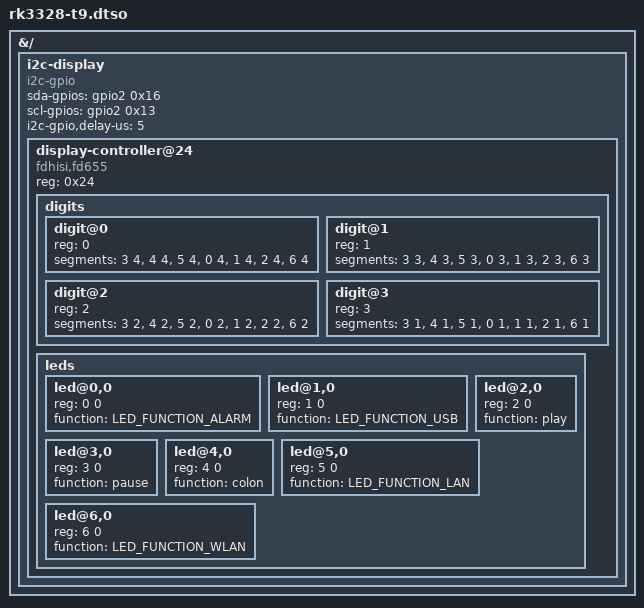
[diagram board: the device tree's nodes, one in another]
/dts-v1/;
/plugin/;

#include <dt-bindings/gpio/gpio.h>
#include <dt-bindings/leds/common.h>

&{/} {

	i2c-display {
		compatible = "i2c-gpio";
		sda-gpios = <&gpio2 0x16 (GPIO_ACTIVE_HIGH | GPIO_OPEN_DRAIN)>;
		scl-gpios = <&gpio2 0x13 (GPIO_ACTIVE_HIGH | GPIO_OPEN_DRAIN)>;
		i2c-gpio,delay-us = <5>;
		#address-cells = <1>;
		#size-cells = <0>;

		display-controller@24 {
			compatible = "fdhisi,fd655";
			reg = <0x24>;

			digits {
				#address-cells = <1>;
				#size-cells = <0>;
				digit@0 {
					reg = <0>;
					segments = <3 4>,
						   <4 4>,
						   <5 4>,
						   <0 4>,
						   <1 4>,
						   <2 4>,
						   <6 4>;
				};
				digit@1 {
					reg = <1>;
					segments = <3 3>,
						   <4 3>,
						   <5 3>,
						   <0 3>,
						   <1 3>,
						   <2 3>,
						   <6 3>;
				};
				digit@2 {
					reg = <2>;
					segments = <3 2>,
						   <4 2>,
						   <5 2>,
						   <0 2>,
						   <1 2>,
						   <2 2>,
						   <6 2>;
				};
				digit@3 {
					reg = <3>;
					segments = <3 1>,
						   <4 1>,
						   <5 1>,
						   <0 1>,
						   <1 1>,
						   <2 1>,
						   <6 1>;
				};
			};

			leds {
				#address-cells = <2>;
				#size-cells = <0>;
				led@0,0 {
					reg = <0 0>;
					function = LED_FUNCTION_ALARM;
				};
				led@1,0 {
					reg = <1 0>;
					function = LED_FUNCTION_USB;
				};
				led@2,0 {
					reg = <2 0>;
					function = "play";
				};
				led@3,0 {
					reg = <3 0>;
					function = "pause";
				};
				led@4,0 {
					reg = <4 0>;
					function = "colon";
				};
				led@5,0 {
					reg = <5 0>;
					function = LED_FUNCTION_LAN;
				};
				led@6,0 {
					reg = <6 0>;
					function = LED_FUNCTION_WLAN;
				};
			};
		};
	};
};
